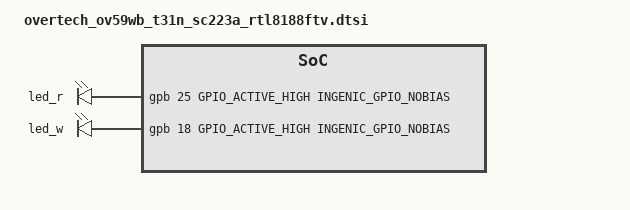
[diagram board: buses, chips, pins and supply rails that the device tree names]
// Overtech OV59WB (T31N, SC223A, RTL8188FTV) per-board GPIO definitions.
// Injected into the kernel 4.4+ device tree; ignored on 3.10.

#include <dt-bindings/gpio/gpio.h>
#include <dt-bindings/pinctrl/ingenic-pinctrl.h>

/ {
	gpio-leds {
		compatible = "gpio-leds";

		led_r {
			label = "led_r";
			gpios = <&gpb 25 GPIO_ACTIVE_HIGH INGENIC_GPIO_NOBIAS>;
			default-state = "off";
		};

		led_w {
			label = "led_w";
			gpios = <&gpb 18 GPIO_ACTIVE_HIGH INGENIC_GPIO_NOBIAS>;
			default-state = "off";
		};
	};
};

/* Card detect; the family tree carries the reference pin. */
&msc0 {
	ingenic,cd-gpios = <&gpb 27 GPIO_ACTIVE_LOW INGENIC_GPIO_PULLUP>;
};
